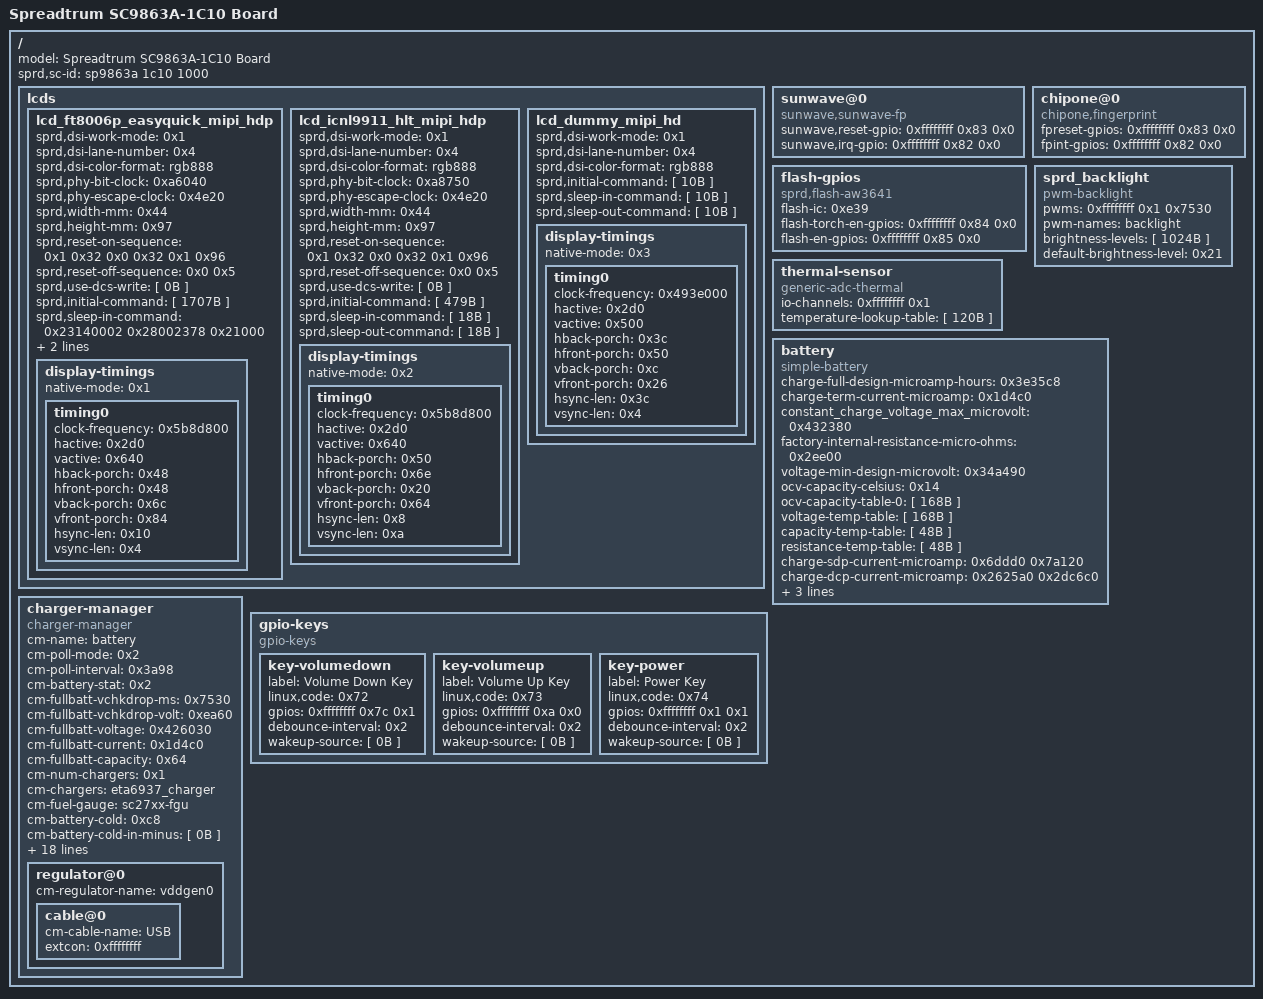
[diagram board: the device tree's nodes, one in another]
/ {
  model = "Spreadtrum SC9863A-1C10 Board";
  compatible = [ 31B ];
  sprd,sc-id = "sp9863a 1c10 1000";
  fragment {
    target-path = "/";
    __overlay__ {
      lcds {
        lcd_ft8006p_easyquick_mipi_hdp {
          sprd,dsi-work-mode = <0x1>;
          sprd,dsi-lane-number = <0x4>;
          sprd,dsi-color-format = "rgb888";
          sprd,phy-bit-clock = <0xa6040>;
          sprd,phy-escape-clock = <0x4e20>;
          sprd,width-mm = <0x44>;
          sprd,height-mm = <0x97>;
          sprd,reset-on-sequence = <0x1 0x32 0x0 0x32 0x1 0x96>;
          sprd,reset-off-sequence = <0x0 0x5>;
          sprd,use-dcs-write = [ 0B ];
          sprd,initial-command = [ 1707B ];
          sprd,sleep-in-command = <0x23140002 0x28002378 0x21000>;
          sprd,sleep-out-command = <0x23780023 0x11002314 0x232900>;
          phandle = <0x20>;
          display-timings {
            native-mode = <0x1>;
            timing0 {
              clock-frequency = <0x5b8d800>;
              hactive = <0x2d0>;
              vactive = <0x640>;
              hback-porch = <0x48>;
              hfront-porch = <0x48>;
              vback-porch = <0x6c>;
              vfront-porch = <0x84>;
              hsync-len = <0x10>;
              vsync-len = <0x4>;
              phandle = <0x1>;
            };
          };
        };
        lcd_icnl9911_hlt_mipi_hdp {
          sprd,dsi-work-mode = <0x1>;
          sprd,dsi-lane-number = <0x4>;
          sprd,dsi-color-format = "rgb888";
          sprd,phy-bit-clock = <0xa8750>;
          sprd,phy-escape-clock = <0x4e20>;
          sprd,width-mm = <0x44>;
          sprd,height-mm = <0x97>;
          sprd,reset-on-sequence = <0x1 0x32 0x0 0x32 0x1 0x96>;
          sprd,reset-off-sequence = <0x0 0x5>;
          sprd,use-dcs-write = [ 0B ];
          sprd,initial-command = [ 479B ];
          sprd,sleep-in-command = [ 18B ];
          sprd,sleep-out-command = [ 18B ];
          phandle = <0x21>;
          display-timings {
            native-mode = <0x2>;
            timing0 {
              clock-frequency = <0x5b8d800>;
              hactive = <0x2d0>;
              vactive = <0x640>;
              hback-porch = <0x50>;
              hfront-porch = <0x6e>;
              vback-porch = <0x20>;
              vfront-porch = <0x64>;
              hsync-len = <0x8>;
              vsync-len = <0xa>;
              phandle = <0x2>;
            };
          };
        };
        lcd_dummy_mipi_hd {
          sprd,dsi-work-mode = <0x1>;
          sprd,dsi-lane-number = <0x4>;
          sprd,dsi-color-format = "rgb888";
          sprd,initial-command = [ 10B ];
          sprd,sleep-in-command = [ 10B ];
          sprd,sleep-out-command = [ 10B ];
          phandle = <0x22>;
          display-timings {
            native-mode = <0x3>;
            timing0 {
              clock-frequency = <0x493e000>;
              hactive = <0x2d0>;
              vactive = <0x500>;
              hback-porch = <0x3c>;
              hfront-porch = <0x50>;
              vback-porch = <0xc>;
              vfront-porch = <0x26>;
              hsync-len = <0x3c>;
              vsync-len = <0x4>;
              phandle = <0x3>;
            };
          };
        };
      };
      sunwave@0 {
        compatible = "sunwave,sunwave-fp";
        sunwave,reset-gpio = <0xffffffff 0x83 0x0>;
        sunwave,irq-gpio = <0xffffffff 0x82 0x0>;
      };
      chipone@0 {
        compatible = "chipone,fingerprint";
        fpreset-gpios = <0xffffffff 0x83 0x0>;
        fpint-gpios = <0xffffffff 0x82 0x0>;
      };
      flash-gpios {
        compatible = "sprd,flash-aw3641";
        flash-ic = <0xe39>;
        flash-torch-en-gpios = <0xffffffff 0x84 0x0>;
        flash-en-gpios = <0xffffffff 0x85 0x0>;
      };
      sprd_backlight {
        compatible = "pwm-backlight";
        pwms = <0xffffffff 0x1 0x7530>;
        pwm-names = "backlight";
        brightness-levels = [ 1024B ];
        default-brightness-level = <0x21>;
        phandle = <0x5>;
      };
      thermal-sensor {
        compatible = "generic-adc-thermal";
        #thermal-sensor-cells = <0x0>;
        io-channels = <0xffffffff 0x1>;
        io-channel-names = "sensor-channel";
        temperature-lookup-table = [ 120B ];
        phandle = <0xc>;
      };
      battery {
        compatible = "simple-battery";
        charge-full-design-microamp-hours = <0x3e35c8>;
        charge-term-current-microamp = <0x1d4c0>;
        constant_charge_voltage_max_microvolt = <0x432380>;
        factory-internal-resistance-micro-ohms = <0x2ee00>;
        voltage-min-design-microvolt = <0x34a490>;
        ocv-capacity-celsius = <0x14>;
        ocv-capacity-table-0 = [ 168B ];
        voltage-temp-table = [ 168B ];
        capacity-temp-table = [ 48B ];
        resistance-temp-table = [ 48B ];
        charge-sdp-current-microamp = <0x6ddd0 0x7a120>;
        charge-dcp-current-microamp = <0x2625a0 0x2dc6c0>;
        charge-cdp-current-microamp = <0x118c30 0x118c30>;
        charge-unknown-current-microamp = <0x6ddd0 0x7a120>;
        phandle = <0x4>;
      };
      charger-manager {
        compatible = "charger-manager";
        cm-name = "battery";
        cm-poll-mode = <0x2>;
        cm-poll-interval = <0x3a98>;
        cm-battery-stat = <0x2>;
        cm-fullbatt-vchkdrop-ms = <0x7530>;
        cm-fullbatt-vchkdrop-volt = <0xea60>;
        cm-fullbatt-voltage = <0x426030>;
        cm-fullbatt-current = <0x1d4c0>;
        cm-fullbatt-capacity = <0x64>;
        cm-num-chargers = <0x1>;
        cm-chargers = "eta6937_charger";
        cm-fuel-gauge = "sc27xx-fgu";
        cm-battery-cold = <0xc8>;
        cm-battery-cold-in-minus = [ 0B ];
        cm-battery-hot = <0x320>;
        cm-battery-temp-diff = <0x64>;
        cm-charging-max = <0x1499700>;
        cm-discharging-max = <0xa4cb80>;
        cm-wdt-interval = <0x3c>;
        cm-shutdown-voltage = <0x2f4d60>;
        cm-tickle-time-out = <0x5dc>;
        cm-one-cap-time = <0x1e>;
        cm-charge-voltage-max = <0x632ea0>;
        cm-charge-voltage-drop = <0xaae60>;
        cm-thermal-zone = "board-thmzone";
        cm-dcp-jeita-temp-table = [ 64B ];
        cm-sdp-jeita-temp-table = [ 64B ];
        cm-cdp-jeita-temp-table = [ 64B ];
        cm-unknown-jeita-temp-table = [ 64B ];
        monitored-battery = <0x4>;
        cm-capacity-track = [ 0B ];
        cm-cap-remap-table = [ 48B ];
        regulator@0 {
          cm-regulator-name = "vddgen0";
          cable@0 {
            cm-cable-name = "USB";
            extcon = <0xffffffff>;
          };
        };
      };
      gpio-keys {
        compatible = "gpio-keys";
        key-volumedown {
          label = "Volume Down Key";
          linux,code = <0x72>;
          gpios = <0xffffffff 0x7c 0x1>;
          debounce-interval = <0x2>;
          wakeup-source = [ 0B ];
        };
        key-volumeup {
          label = "Volume Up Key";
          linux,code = <0x73>;
          gpios = <0xffffffff 0xa 0x0>;
          debounce-interval = <0x2>;
          wakeup-source = [ 0B ];
        };
        key-power {
          label = "Power Key";
          linux,code = <0x74>;
          gpios = <0xffffffff 0x1 0x1>;
          debounce-interval = <0x2>;
          wakeup-source = [ 0B ];
        };
      };
    };
  };
  fragment@0 {
    target = <0xffffffff>;
    __overlay__ {
      bootargs_ext = "androidboot.hardware=s9863a1c10 androidboot.dtbo_idx=0";
    };
  };
  fragment@1 {
    target = <0xffffffff>;
    __overlay__ {
      logobuffer@fd580000 {
        reg = <0x0 0xfd580000 0x0 0x7e9000>;
        phandle = <0x1f>;
      };
      camera@fdd69000 {
        reg = <0x0 0xfdd69000 0x0 0xa00000>;
        phandle = <0x1e>;
      };
      framebuffer@fe769000 {
        reg = <0x0 0xfe769000 0x0 0x1817000>;
        phandle = <0x1d>;
      };
    };
  };
  fragment@2 {
    target = <0xffffffff>;
    __overlay__ {
      sprd,backlight = <0x5>;
      avdd-gpio = <0xffffffff 0x59 0x0>;
      reset-gpio = <0xffffffff 0x32 0x0>;
    };
  };
  fragment@3 {
    target = <0xffffffff>;
    __overlay__ {
      sprd-scene = [ 46B ];
      sprd-freq = <0x3a5 0x190 0xe9 0x190 0x26e 0x3a5>;
    };
  };
  fragment@4 {
    target = <0xffffffff>;
    __overlay__ {
      id-gpio = <0xffffffff 0x4 0x0>;
    };
  };
  fragment@5 {
    target = <0xffffffff>;
    __overlay__ {
      extcon = <0xffffffff>;
      vbus-supply = <0x6>;
    };
  };
  fragment@6 {
    target = <0xffffffff>;
    __overlay__ {
      monitored-battery = <0x4>;
      sprd,calib-resistance-real = <0x4e20>;
      sprd,calib-resistance-spec = <0x4e20>;
      first-calib-voltage = <0x36ee80>;
      first-calib-capacity = <0x32>;
    };
  };
  fragment@7 {
    target = <0xffffffff>;
    __overlay__ {
      cd-gpios = <0xffffffff 0x9 0x1>;
    };
  };
  fragment@8 {
    target = <0xffffffff>;
    __overlay__ {
      status = "okay";
      clock-frequency = <0x61a80>;
      sensor-main@20 {
        compatible = "sprd,sensor-main";
        reg = <0x20>;
        clock-names = [ 51B ];
        clocks = [ 44B ];
        vddio-supply = <0xffffffff>;
        vddcama-supply = <0xffffffff>;
        vddcamd-supply = <0xffffffff>;
        vddcammot-supply = <0xffffffff>;
        avdd-gpios = <0xffffffff 0x3e 0x0>;
        mipi-switch-mode-gpios = <0xffffffff 0x1e 0x1>;
        mipi-switch-en-gpios = <0xffffffff 0x1d 0x0>;
        sprd,phyid = <0x1>;
        csi = <0xffffffff>;
        reset-gpios = <0xffffffff 0x2c 0x0>;
        power-down-gpios = <0xffffffff 0x2e 0x0>;
        phandle = <0x23>;
      };
      sensor-sub2@30 {
        compatible = "sprd,sensor-sub2";
        reg = <0x30>;
        clock-names = [ 51B ];
        clocks = [ 44B ];
        vddio-supply = <0xffffffff>;
        vddcama-supply = <0xffffffff>;
        vddcamd-supply = <0xffffffff>;
        vddcammot-supply = <0xffffffff>;
        sprd,phyid = <0x2>;
        csi = <0xffffffff>;
        iovdd-gpios = <0xffffffff 0xf 0x0>;
        dvdd-gpios = <0xffffffff 0x5 0x0>;
        reset-gpios = <0xffffffff 0x10 0x0>;
        power-down-gpios = <0xffffffff 0x39 0x0>;
        phandle = <0x24>;
      };
    };
  };
  fragment@9 {
    target = <0xffffffff>;
    __overlay__ {
      status = "okay";
      clock-frequency = <0x61a80>;
      sensor-sub@20 {
        compatible = "sprd,sensor-sub";
        reg = <0x20>;
        clock-names = [ 51B ];
        clocks = [ 44B ];
        vddio-supply = <0xffffffff>;
        vddcama-supply = <0xffffffff>;
        vddcamd-supply = <0xffffffff>;
        vddcammot-supply = <0xffffffff>;
        sprd,phyid = <0x1>;
        csi = <0xffffffff>;
        avdd-gpios = <0xffffffff 0x3e 0x0>;
        mipi-switch-mode-gpios = <0xffffffff 0x1e 0x0>;
        mipi-switch-en-gpios = <0xffffffff 0x1d 0x0>;
        reset-gpios = <0xffffffff 0x29 0x0>;
        power-down-gpios = <0xffffffff 0x28 0x0>;
        phandle = <0x25>;
      };
      sensor-main2@6C {
        compatible = "sprd,sensor-main2";
        reg = <0x6c>;
        clock-names = [ 51B ];
        clocks = [ 44B ];
        vddio-supply = <0xffffffff>;
        vddcama-supply = <0xffffffff>;
        vddcamd-supply = <0xffffffff>;
        vddcammot-supply = <0xffffffff>;
        sprd,phyid = <0x4>;
        csi = <0xffffffff>;
        iovdd-gpios = <0xffffffff 0xf 0x0>;
        dvdd-gpios = <0xffffffff 0x5 0x0>;
        reset-gpios = <0xffffffff 0x38 0x0>;
        power-down-gpios = <0xffffffff 0x3b 0x0>;
        phandle = <0x26>;
      };
      sensor-main3@2a {
        compatible = "sprd,sensor-main3";
        reg = <0x2a>;
        clock-names = [ 51B ];
        clocks = [ 44B ];
        vddio-supply = <0xffffffff>;
        vddcama-supply = <0xffffffff>;
        vddcamd-supply = <0xffffffff>;
        vddcammot-supply = <0xffffffff>;
        sprd,phyid = <0x3>;
        csi = <0xffffffff>;
        dvdd-gpios = <0xffffffff 0x8e 0x0>;
        reset-gpios = <0xffffffff 0x2d 0x0>;
        power-down-gpios = <0xffffffff 0x2f 0x0>;
        phandle = <0x27>;
      };
    };
  };
  fragment@10 {
    target = <0xffffffff>;
    __overlay__ {
      status = "okay";
      clock-frequency = <0x186a0>;
      focaltech_ts@38 {
        compatible = "focaltech,focaltech_ts";
        reg = <0x38>;
        gpios = <0xffffffff 0x91 0x0 0xffffffff 0x90 0x0>;
        vdd_name = "vdd28";
        virtualkeys = [ 48B ];
        TP_MAX_X = <0x2d0>;
        TP_MAX_Y = <0x5a0>;
      };
      chipone_tddi@48 {
        compatible = "chipone-tddi";
        reg = <0x48>;
        gpios = <0xffffffff 0x91 0x0 0xffffffff 0x90 0x0>;
        vdd_name = "vdd28";
        virtualkeys = [ 48B ];
        TP_MAX_X = <0x2d0>;
        TP_MAX_Y = <0x5a0>;
      };
      goodix_ts@5d {
        compatible = "Goodix,goodix_ts";
        reg = <0x5d>;
        gpios = <0xffffffff 0x91 0x0 0xffffffff 0x90 0x0>;
        vdd_name = "vdd28";
        virtualkeys = [ 48B ];
        TP_MAX_X = <0x2d0>;
        TP_MAX_Y = <0x5a0>;
      };
    };
  };
  fragment@11 {
    target = <0xffffffff>;
    __overlay__ {
      status = "okay";
      clock-frequency = <0x61a80>;
      charger@6a {
        compatible = "eta,eta6937_chg";
        reg = <0x6a>;
        phys = <0xffffffff>;
        monitored-battery = <0x4>;
        chg-enable-gpios = <0xffffffff 0x20 0x0>;
        extcon = <0xffffffff>;
        phandle = <0x28>;
        otg-vbus {
          regulator-name = "vddvbus";
          phandle = <0x6>;
        };
      };
      bias_lcm@3e {
        compatible = "bias_lcm,tps65132_power";
        reg = <0x3e>;
        fv-en-gpios = <0xffffffff 0x59 0x0>;
        phandle = <0x29>;
      };
    };
  };
  fragment@12 {
    target = <0xffffffff>;
    __overlay__ {
      status = "okay";
      clock-frequency = <0x61a80>;
      regulator@60 {
        compatible = "fcs,fan53555";
        reg = <0x60>;
        regulator-name = "fan53555";
        regulator-min-microvolt = <0x93378>;
        regulator-max-microvolt = <0x1587b8>;
        regulator-ramp-delay = <0xfa00>;
        regulator-always-on = [ 0B ];
        fcs,suspend-voltage-selector = <0x1>;
        phandle = <0x2a>;
      };
    };
  };
  fragment@13 {
    target = <0xffffffff>;
    __overlay__ {
      cd-gpios = <0xffffffff 0x9 0x0>;
    };
  };
  fragment@14 {
    target = <0xffffffff>;
    __overlay__ {
      status = "okay";
      sprd,dcam-superzoom = <0x0>;
    };
  };
  fragment@15 {
    target = <0xffffffff>;
    __overlay__ {
      hwdvfs_dev = <0x7 0x8 0x9>;
      cluster@0 {
        reg = <0x0>;
        dcdc-ctrl = <0xa>;
        phandle = <0x7>;
      };
      cluster@1 {
        reg = <0x1>;
        dcdc-ctrl = <0xb>;
        phandle = <0x8>;
      };
      dsu@0 {
        reg = <0x0>;
        dcdc-ctrl = <0xb>;
        phandle = <0x9>;
      };
      dcdc-controller@0 {
        reg = <0x0 0x0>;
        volt-via-adi = [ 0B ];
        volt-hold-us = <0x32>;
        volt-pause-us = <0x5>;
        volt-timeout-us = <0x320>;
        volt-stable-us = <0x5>;
        volt-max-step-microvolt = <0x61a8>;
        phandle = <0xb>;
      };
      dcdc-controller@1 {
        reg = <0x1 0x2>;
        volt-via-i2c = [ 0B ];
        volt-hold-us = <0x19>;
        volt-pause-us = <0x14>;
        volt-timeout-us = <0x320>;
        volt-stable-us = <0x19>;
        volt-max-step-microvolt = <0x124f84>;
        phandle = <0xa>;
      };
    };
  };
  fragment@16 {
    target = <0xffffffff>;
    __overlay__ {
      board-thmzone {
        polling-delay-passive = <0x0>;
        polling-delay = <0x0>;
        thermal-sensors = <0xc>;
        phandle = <0x2b>;
      };
    };
  };
  fragment@17 {
    target = <0xffffffff>;
    __overlay__ {
      regulator-always-on = [ 0B ];
    };
  };
  fragment@18 {
    target = <0xffffffff>;
    __overlay__ {
      regulator-always-on = [ 0B ];
    };
  };
  fragment@19 {
    target = <0xffffffff>;
    __overlay__ {
      regulator-always-on = [ 0B ];
    };
  };
  fragment@20 {
    target = <0xffffffff>;
    __overlay__ {
      regulator-always-on = [ 0B ];
    };
  };
  fragment@21 {
    target = <0xffffffff>;
    __overlay__ {
      status = "disabled";
    };
  };
  fragment@22 {
    target = <0xffffffff>;
    __overlay__ {
      pinctrl-names = [ 99B ];
      pinctrl-0 = <0xd>;
      pinctrl-1 = <0xe>;
      pinctrl-2 = <0xf>;
      pinctrl-3 = <0x10>;
      pinctrl-4 = <0x11>;
      pinctrl-5 = <0x12>;
      pinctrl-6 = <0x13>;
      pinctrl-7 = <0x14>;
      pinctrl-8 = <0x15>;
      pinctrl-9 = <0x16>;
      pinctrl-10 = <0x17 0x18 0x19 0x1a 0x1b 0x1c>;
      keyout0 {
        pins = "SHARKL3_KEYOUT0";
        function = "func4";
        phandle = <0xd>;
      };
      keyout1 {
        pins = "SHARKL3_KEYOUT1";
        function = "func4";
        phandle = <0xe>;
      };
      keyout2 {
        pins = "SHARKL3_KEYOUT2";
        function = "func4";
        phandle = <0xf>;
      };
      keyin0 {
        pins = "SHARKL3_KEYIN0";
        function = "func4";
        phandle = <0x10>;
      };
      keyin1 {
        pins = "SHARKL3_KEYIN1";
        function = "func4";
        phandle = <0x11>;
      };
      keyin2 {
        pins = "SHARKL3_KEYIN2";
        function = "func4";
        phandle = <0x12>;
      };
      extint0 {
        pins = "SHARKL3_EXTINT0";
        function = "func4";
        phandle = <0x13>;
      };
      extint1 {
        pins = "SHARKL3_EXTINT1";
        function = "func4";
        phandle = <0x14>;
      };
      scl3 {
        pins = "SHARKL3_SCL3";
        function = "func4";
        phandle = <0x15>;
      };
      sda3 {
        pins = "SHARKL3_SDA3";
        function = "func4";
        phandle = <0x16>;
      };
      rfsen0 {
        pins = "SHARKL3_RFSEN0";
        function = "func4";
        phandle = <0x17>;
      };
      rfsck0 {
        pins = "SHARKL3_RFSCK0";
        function = "func4";
        phandle = <0x18>;
      };
      rfsda0 {
        pins = "SHARKL3_RFSDA0";
        function = "func4";
        phandle = <0x19>;
      };
      rfsen1 {
        pins = "SHARKL3_RFSEN1";
        function = "func4";
        phandle = <0x1a>;
      };
      rfsck1 {
        pins = "SHARKL3_RFSCK1";
        function = "func4";
        phandle = <0x1b>;
      };
      rfsda1 {
        pins = "SHARKL3_RFSDA1";
        function = "func4";
        phandle = <0x1c>;
      };
    };
  };
  fragment@23 {
    target = <0xffffffff>;
    __overlay__ {
      status = "okay";
      sprd,spk-route-hp = [ 0B ];
    };
  };
  fragment@24 {
    target = <0xffffffff>;
    __overlay__ {
      status = "okay";
      sprd,spk-ext-pa-info = <0x0 0x0 0x4 0x0>;
      sprd,spk-ext-pa-gpio = <0xffffffff 0x9c 0x0>;
    };
  };
  fragment@25 {
    target = <0xffffffff>;
    __overlay__ {
      heap@3 {
        reg = <0x3>;
        label = "carveout_fb";
        type = <0x2>;
        memory-region = <0x1d>;
      };
      heap@4 {
        reg = <0x4>;
        label = "carveout_camera";
        type = <0x2>;
        memory-region = <0x1e>;
      };
    };
  };
  fragment@26 {
    target = <0xffffffff>;
    __overlay__ {
      sprd,logo-memory = <0x1f>;
    };
  };
  __symbols__ {
    lcd_ft8006p_easyquick_mipi_hdp = "/fragment/__overlay__/lcds/lcd_ft8006p_easyquick_mipi_hdp";
    ft8006p_easyquick_timing0 = "/fragment/__overlay__/lcds/lcd_ft8006p_easyquick_mipi_hdp/display-timings/timing0";
    lcd_icnl9911_hlt_mipi_hdp = "/fragment/__overlay__/lcds/lcd_icnl9911_hlt_mipi_hdp";
    icnl9911_hlt_timing0 = "/fragment/__overlay__/lcds/lcd_icnl9911_hlt_mipi_hdp/display-timings/timing0";
    lcd_dummy_mipi_hd = "/fragment/__overlay__/lcds/lcd_dummy_mipi_hd";
    dummy_timing0 = "/fragment/__overlay__/lcds/lcd_dummy_mipi_hd/display-timings/timing0";
    pwm_backlight = "/fragment/__overlay__/sprd_backlight";
    tboard_thermistor = "/fragment/__overlay__/thermal-sensor";
    bat = "/fragment/__overlay__/battery";
    logo_reserved = "/fragment@1/__overlay__/logobuffer@fd580000";
    camera_reserved = "/fragment@1/__overlay__/camera@fdd69000";
    fb_reserved = "/fragment@1/__overlay__/framebuffer@fe769000";
    sensor_main = "/fragment@8/__overlay__/sensor-main@20";
    sensor_sub2 = "/fragment@8/__overlay__/sensor-sub2@30";
    sensor_sub = "/fragment@9/__overlay__/sensor-sub@20";
    sensor_main2 = "/fragment@9/__overlay__/sensor-main2@6C";
    sensor_main3 = "/fragment@9/__overlay__/sensor-main3@2a";
    eta6937_chg = "/fragment@11/__overlay__/charger@6a";
    vddvbus = "/fragment@11/__overlay__/charger@6a/otg-vbus";
    tps65132 = "/fragment@11/__overlay__/bias_lcm@3e";
    fan53555_dcdc = "/fragment@12/__overlay__/regulator@60";
    hwdvfs_cluster0 = "/fragment@15/__overlay__/cluster@0";
    hwdvfs_cluster1 = "/fragment@15/__overlay__/cluster@1";
    hwdvfs_dsu = "/fragment@15/__overlay__/dsu@0";
    dcdc_ctrl0 = "/fragment@15/__overlay__/dcdc-controller@0";
    dcdc_ctrl1 = "/fragment@15/__overlay__/dcdc-controller@1";
    bd_thmzone = "/fragment@16/__overlay__/board-thmzone";
    gpio_121 = "/fragment@22/__overlay__/keyout0";
    gpio_122 = "/fragment@22/__overlay__/keyout1";
    gpio_123 = "/fragment@22/__overlay__/keyout2";
    gpio_124 = "/fragment@22/__overlay__/keyin0";
    gpio_125 = "/fragment@22/__overlay__/keyin1";
    gpio_126 = "/fragment@22/__overlay__/keyin2";
    gpio_144 = "/fragment@22/__overlay__/extint0";
    gpio_145 = "/fragment@22/__overlay__/extint1";
    gpio_146 = "/fragment@22/__overlay__/scl3";
    gpio_147 = "/fragment@22/__overlay__/sda3";
    shutdown0 = "/fragment@22/__overlay__/rfsen0";
    shutdown1 = "/fragment@22/__overlay__/rfsck0";
    shutdown2 = "/fragment@22/__overlay__/rfsda0";
    shutdown3 = "/fragment@22/__overlay__/rfsen1";
    shutdown4 = "/fragment@22/__overlay__/rfsck1";
    shutdown5 = "/fragment@22/__overlay__/rfsda1";
  };
  __fixups__ {
    ap_gpio = [ 2054B ];
    pwms = "/fragment/__overlay__/sprd_backlight:pwms:0";
    pmic_adc = "/fragment/__overlay__/thermal-sensor:io-channels:0";
    pmic_typec = "/fragment/__overlay__/charger-manager/regulator@0/cable@0:extcon:0";
    pmic_eic = [ 103B ];
    chosen = "/fragment@0:target:0";
    reserved_memory = "/fragment@1:target:0";
    panel = "/fragment@2:target:0";
    ddr_dfs = "/fragment@3:target:0";
    extcon_gpio = [ 99B ];
    eic_debounce = "/fragment@4/__overlay__:id-gpio:0";
    usb = "/fragment@5:target:0";
    pmic_fgu = "/fragment@6:target:0";
    sdio0 = [ 43B ];
    eic_async = [ 71B ];
    i2c0 = "/fragment@8:target:0";
    aon_clk = [ 241B ];
    mm_gate = [ 241B ];
    pll = [ 738B ];
    ext_26m = [ 246B ];
    vddcamio = [ 271B ];
    vddcama = [ 281B ];
    vddcamd = [ 281B ];
    vddcammot = [ 291B ];
    csi0 = [ 89B ];
    csi1 = [ 137B ];
    i2c1 = "/fragment@9:target:0";
    i2c3 = "/fragment@10:target:0";
    i2c4 = "/fragment@11:target:0";
    hsphy = "/fragment@11/__overlay__/charger@6a:phys:0";
    i2c7 = "/fragment@12:target:0";
    dcam = "/fragment@14:target:0";
    sprd_hwdvfs = "/fragment@15:target:0";
    thm_zone = "/fragment@16:target:0";
    vdd18 = "/fragment@17:target:0";
    vddrf18 = "/fragment@18:target:0";
    vddrf125 = "/fragment@19:target:0";
    vddldomem = "/fragment@20:target:0";
    vddsim2 = "/fragment@21:target:0";
    pin_controller = "/fragment@22:target:0";
    sprd_headset = "/fragment@23:target:0";
    sound_vbc_r1p0v3_sprd_codec = "/fragment@24:target:0";
    ion = "/fragment@25:target:0";
    dpu = "/fragment@26:target:0";
  };
  __local_fixups__ {
    fragment {
      __overlay__ {
        lcds {
          lcd_ft8006p_easyquick_mipi_hdp {
            display-timings {
              native-mode = <0x0>;
            };
          };
          lcd_icnl9911_hlt_mipi_hdp {
            display-timings {
              native-mode = <0x0>;
            };
          };
          lcd_dummy_mipi_hd {
            display-timings {
              native-mode = <0x0>;
            };
          };
        };
        charger-manager {
          monitored-battery = <0x0>;
        };
      };
    };
    fragment@2 {
      __overlay__ {
        sprd,backlight = <0x0>;
      };
    };
    fragment@5 {
      __overlay__ {
        vbus-supply = <0x0>;
      };
    };
    fragment@6 {
      __overlay__ {
        monitored-battery = <0x0>;
      };
    };
    fragment@11 {
      __overlay__ {
        charger@6a {
          monitored-battery = <0x0>;
        };
      };
    };
    fragment@15 {
      __overlay__ {
        hwdvfs_dev = <0x0 0x4 0x8>;
        cluster@0 {
          dcdc-ctrl = <0x0>;
        };
        cluster@1 {
          dcdc-ctrl = <0x0>;
        };
        dsu@0 {
          dcdc-ctrl = <0x0>;
        };
      };
    };
    fragment@16 {
      __overlay__ {
        board-thmzone {
          thermal-sensors = <0x0>;
        };
      };
    };
    fragment@22 {
      __overlay__ {
        pinctrl-0 = <0x0>;
        pinctrl-1 = <0x0>;
        pinctrl-2 = <0x0>;
        pinctrl-3 = <0x0>;
        pinctrl-4 = <0x0>;
        pinctrl-5 = <0x0>;
        pinctrl-6 = <0x0>;
        pinctrl-7 = <0x0>;
        pinctrl-8 = <0x0>;
        pinctrl-9 = <0x0>;
        pinctrl-10 = <0x0 0x4 0x8 0xc 0x10 0x14>;
      };
    };
    fragment@25 {
      __overlay__ {
        heap@3 {
          memory-region = <0x0>;
        };
        heap@4 {
          memory-region = <0x0>;
        };
      };
    };
    fragment@26 {
      __overlay__ {
        sprd,logo-memory = <0x0>;
      };
    };
  };
};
